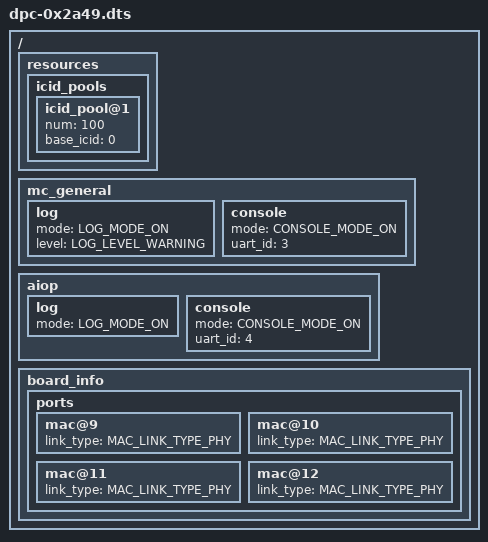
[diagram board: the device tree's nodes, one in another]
/dts-v1/;
/* DPC */
/ {
	resources {
		icid_pools {
			icid_pool@1 {
				num = <100>;
				base_icid = <0>;
			};
		};
	};
	mc_general {
		log {
			mode = "LOG_MODE_ON";
			level = "LOG_LEVEL_WARNING";
		};
		console {
			mode = "CONSOLE_MODE_ON";
			uart_id = <3>;
		};
	};
	aiop {
		log {
			mode = "LOG_MODE_ON";
		};
		console {
			mode = "CONSOLE_MODE_ON";
			uart_id = <4>;
		};
	};
	board_info {
		ports {
			/* For QDS SerDes 0x2a_49: 4 SGMII ports. */
			mac@9 {
				link_type = "MAC_LINK_TYPE_PHY";
			};
			mac@10 {
				link_type = "MAC_LINK_TYPE_PHY";
			};
			mac@11 {
				link_type = "MAC_LINK_TYPE_PHY";
			};
			mac@12 {
				link_type = "MAC_LINK_TYPE_PHY";
			};
		};
	};
};
